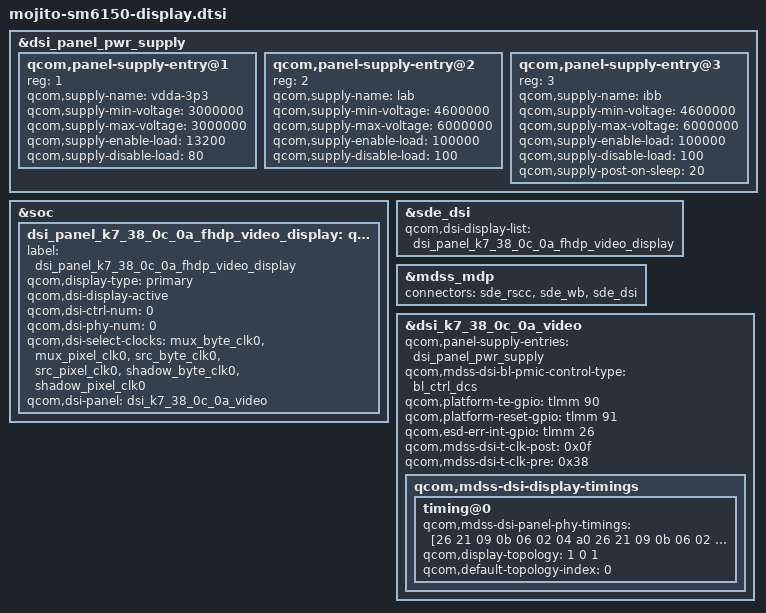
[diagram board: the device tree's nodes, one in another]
/*
 * Copyright (c) 2019, The Linux Foundation. All rights reserved.
 * Copyright (C) 2021 XiaoMi, Inc.
 *
 * This program is free software; you can redistribute it and/or modify
 * it under the terms of the GNU General Public License version 2 and
 * only version 2 as published by the Free Software Foundation.
 *
 * This program is distributed in the hope that it will be useful,
 * but WITHOUT ANY WARRANTY; without even the implied warranty of
 * MERCHANTABILITY or FITNESS FOR A PARTICULAR PURPOSE.  See the
 * GNU General Public License for more details.
 */

#include "display/dsi_panel_k7_38_0c_0a_fhdp_video.dtsi"

&dsi_panel_pwr_supply {
	qcom,panel-supply-entry@1 {
		reg = <1>;
		qcom,supply-name = "vdda-3p3";
		qcom,supply-min-voltage = <3000000>;
		qcom,supply-max-voltage = <3000000>;
		qcom,supply-enable-load = <13200>;
		qcom,supply-disable-load = <80>;
	};

	qcom,panel-supply-entry@2 {
		reg = <2>;
		qcom,supply-name = "lab";
		qcom,supply-min-voltage = <4600000>;
		qcom,supply-max-voltage = <6000000>;
		qcom,supply-enable-load = <100000>;
		qcom,supply-disable-load = <100>;
	};

	qcom,panel-supply-entry@3 {
		reg = <3>;
		qcom,supply-name = "ibb";
		qcom,supply-min-voltage = <4600000>;
		qcom,supply-max-voltage = <6000000>;
		qcom,supply-enable-load = <100000>;
		qcom,supply-disable-load = <100>;
		qcom,supply-post-on-sleep = <20>;
	};
};

&soc {
	dsi_panel_k7_38_0c_0a_fhdp_video_display: qcom,dsi-display@10 {
		label = "dsi_panel_k7_38_0c_0a_fhdp_video_display";
		qcom,display-type = "primary";
		qcom,dsi-display-active;
		qcom,dsi-ctrl-num = <0>;
		qcom,dsi-phy-num = <0>;
		qcom,dsi-select-clocks = "mux_byte_clk0", "mux_pixel_clk0",
			"src_byte_clk0", "src_pixel_clk0",
			"shadow_byte_clk0", "shadow_pixel_clk0";
		qcom,dsi-panel = <&dsi_k7_38_0c_0a_video>;
	};
};

&sde_dsi {
	qcom,dsi-display-list = <&dsi_panel_k7_38_0c_0a_fhdp_video_display>;
};

&mdss_mdp {
	connectors = <&sde_rscc &sde_wb &sde_dsi>;
};

&dsi_k7_38_0c_0a_video {
	qcom,panel-supply-entries = <&dsi_panel_pwr_supply>;
	qcom,mdss-dsi-bl-pmic-control-type = "bl_ctrl_dcs";
	qcom,platform-te-gpio = <&tlmm 90 0>;
	qcom,platform-reset-gpio = <&tlmm 91 0>;
	qcom,esd-err-int-gpio = <&tlmm 26 0>;
	qcom,mdss-dsi-t-clk-post = <0x0f>;
	qcom,mdss-dsi-t-clk-pre = <0x38>;
	qcom,mdss-dsi-display-timings {
		timing@0{
			qcom,mdss-dsi-panel-phy-timings =
			       [26 21 09 0b 06 02 04 a0
				26 21 09 0b 06 02 04 a0
				26 21 09 0b 06 02 04 a0
				26 21 09 0b 06 02 04 a0
				26 20 0a 0b 06 02 04 a0];
			qcom,display-topology = <1 0 1>;
			qcom,default-topology-index = <0>;
		};
	};
};
